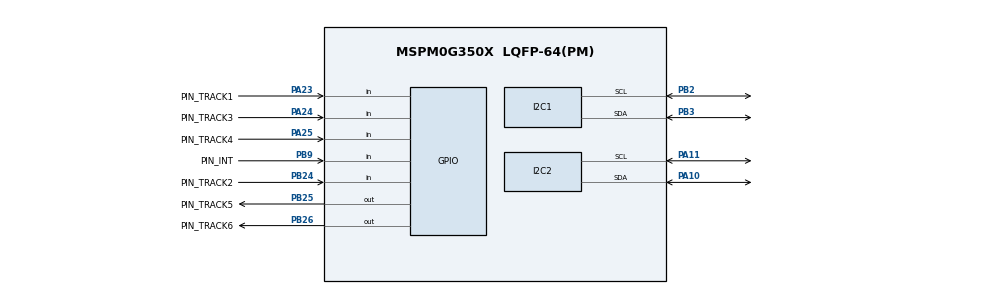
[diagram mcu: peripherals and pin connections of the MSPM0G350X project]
/**
 * @cliArgs --device "MSPM0G350X" --part "Default" --package "LQFP-64(PM)" --product "mspm0_sdk@2.05.01.00"
 * @versions {"tool":"1.24.0+4110"}
 */

/**
 * Import the modules used in this configuration.
 */
const GPIO   = scripting.addModule("/ti/driverlib/GPIO", {}, false);
const GPIO1  = GPIO.addInstance();
const GPIO2  = GPIO.addInstance();
const GPIO3  = GPIO.addInstance();
const GPIO4  = GPIO.addInstance();
const GPIO5  = GPIO.addInstance();
const GPIO6  = GPIO.addInstance();
const I2C    = scripting.addModule("/ti/driverlib/I2C", {}, false);
const I2C1   = I2C.addInstance();
const I2C2   = I2C.addInstance();
const PWM    = scripting.addModule("/ti/driverlib/PWM", {}, false);
const PWM1   = PWM.addInstance();
const PWM2   = PWM.addInstance();
const SYSCTL = scripting.addModule("/ti/driverlib/SYSCTL");
const UART   = scripting.addModule("/ti/driverlib/UART", {}, false);
const UART1  = UART.addInstance();

/**
 * Write custom configuration values to the imported modules.
 */
const divider7       = system.clockTree["PLL_PDIV"];
divider7.divideValue = 2;

const divider9       = system.clockTree["UDIV"];
divider9.divideValue = 2;

const multiplier2         = system.clockTree["PLL_QDIV"];
multiplier2.multiplyValue = 5;

const mux8       = system.clockTree["HSCLKMUX"];
mux8.inputSelect = "HSCLKMUX_SYSPLL2X";

GPIO1.$name                   = "GPIO_MOTOR";
GPIO1.associatedPins.create(5);
GPIO1.associatedPins[0].$name = "PIN_FL1";
GPIO1.associatedPins[1].$name = "PIN_FL2";
GPIO1.associatedPins[2].$name = "PIN_FR1";
GPIO1.associatedPins[3].$name = "PIN_FR2";
GPIO1.associatedPins[4].$name = "PIN_FSTBY";

const Board = scripting.addModule("/ti/driverlib/Board", {}, false);

GPIO2.$name                          = "GPIO_LED";
GPIO2.associatedPins[0].$name        = "PIN_LED1";
GPIO2.associatedPins[0].assignedPort = "PORTB";
GPIO2.associatedPins[0].assignedPin  = "22";

GPIO3.$name                          = "GPIO_BUTTON";
GPIO3.associatedPins[0].$name        = "PIN_S2";
GPIO3.associatedPins[0].direction    = "INPUT";
GPIO3.associatedPins[0].assignedPort = "PORTB";
GPIO3.associatedPins[0].assignedPin  = "21";

GPIO4.$name                               = "GPIO_LSM6DSV16X";
GPIO4.associatedPins[0].direction         = "INPUT";
GPIO4.associatedPins[0].$name             = "PIN_INT";
GPIO4.associatedPins[0].interruptEn       = true;
GPIO4.associatedPins[0].interruptPriority = "3";
GPIO4.associatedPins[0].polarity          = "RISE";
GPIO4.associatedPins[0].pin.$assign       = "PB9";

GPIO5.$name                   = "GPIO_BUZZER";
GPIO5.associatedPins[0].$name = "PIN_buzzer";

GPIO6.$name                         = "GPIO_TRACK";
GPIO6.associatedPins.create(6);
GPIO6.associatedPins[0].$name       = "PIN_TRACK1";
GPIO6.associatedPins[0].direction   = "INPUT";
GPIO6.associatedPins[0].pin.$assign = "PA23";
GPIO6.associatedPins[1].$name       = "PIN_TRACK2";
GPIO6.associatedPins[1].direction   = "INPUT";
GPIO6.associatedPins[1].pin.$assign = "PB24";
GPIO6.associatedPins[2].$name       = "PIN_TRACK3";
GPIO6.associatedPins[2].direction   = "INPUT";
GPIO6.associatedPins[2].pin.$assign = "PA24";
GPIO6.associatedPins[3].$name       = "PIN_TRACK4";
GPIO6.associatedPins[3].direction   = "INPUT";
GPIO6.associatedPins[3].pin.$assign = "PA25";
GPIO6.associatedPins[4].$name       = "PIN_TRACK5";
GPIO6.associatedPins[4].pin.$assign = "PB25";
GPIO6.associatedPins[5].$name       = "PIN_TRACK6";
GPIO6.associatedPins[5].pin.$assign = "PB26";

I2C1.$name                             = "I2C_OLED";
I2C1.basicEnableController             = true;
I2C1.basicControllerStandardBusSpeed   = "Fast";
I2C1.peripheral.$assign                = "I2C1";
I2C1.peripheral.sdaPin.$assign         = "PB3";
I2C1.peripheral.sclPin.$assign         = "PB2";
I2C1.sdaPinConfig.hideOutputInversion  = scripting.forceWrite(false);
I2C1.sdaPinConfig.onlyInternalResistor = scripting.forceWrite(false);
I2C1.sdaPinConfig.passedPeripheralType = scripting.forceWrite("Digital");
I2C1.sdaPinConfig.$name                = "ti_driverlib_gpio_GPIOPinGeneric6";
I2C1.sclPinConfig.hideOutputInversion  = scripting.forceWrite(false);
I2C1.sclPinConfig.onlyInternalResistor = scripting.forceWrite(false);
I2C1.sclPinConfig.passedPeripheralType = scripting.forceWrite("Digital");
I2C1.sclPinConfig.$name                = "ti_driverlib_gpio_GPIOPinGeneric7";

I2C2.$name                             = "I2C_LSM6DSV16X";
I2C2.basicEnableController             = true;
I2C2.basicControllerStandardBusSpeed   = "FastPlus";
I2C2.peripheral.sdaPin.$assign         = "PA10";
I2C2.peripheral.sclPin.$assign         = "PA11";
I2C2.sdaPinConfig.hideOutputInversion  = scripting.forceWrite(false);
I2C2.sdaPinConfig.onlyInternalResistor = scripting.forceWrite(false);
I2C2.sdaPinConfig.passedPeripheralType = scripting.forceWrite("Digital");
I2C2.sdaPinConfig.$name                = "ti_driverlib_gpio_GPIOPinGeneric8";
I2C2.sclPinConfig.hideOutputInversion  = scripting.forceWrite(false);
I2C2.sclPinConfig.onlyInternalResistor = scripting.forceWrite(false);
I2C2.sclPinConfig.passedPeripheralType = scripting.forceWrite("Digital");
I2C2.sclPinConfig.$name                = "ti_driverlib_gpio_GPIOPinGeneric9";

PWM1.$name                              = "PWM_MOTOR";
PWM1.timerCount                         = 8000;
PWM1.clockPrescale                      = 10;
PWM1.peripheral.$assign                 = "TIMA0";
PWM1.PWM_CHANNEL_0.$name                = "ti_driverlib_pwm_PWMTimerCC0";
PWM1.PWM_CHANNEL_0.dutyCycle            = 50;
PWM1.PWM_CHANNEL_1.$name                = "ti_driverlib_pwm_PWMTimerCC1";
PWM1.PWM_CHANNEL_1.dutyCycle            = 50;
PWM1.ccp0PinConfig.direction            = scripting.forceWrite("OUTPUT");
PWM1.ccp0PinConfig.hideOutputInversion  = scripting.forceWrite(false);
PWM1.ccp0PinConfig.onlyInternalResistor = scripting.forceWrite(false);
PWM1.ccp0PinConfig.passedPeripheralType = scripting.forceWrite("Digital");
PWM1.ccp0PinConfig.$name                = "ti_driverlib_gpio_GPIOPinGeneric0";
PWM1.ccp1PinConfig.direction            = scripting.forceWrite("OUTPUT");
PWM1.ccp1PinConfig.hideOutputInversion  = scripting.forceWrite(false);
PWM1.ccp1PinConfig.onlyInternalResistor = scripting.forceWrite(false);
PWM1.ccp1PinConfig.passedPeripheralType = scripting.forceWrite("Digital");
PWM1.ccp1PinConfig.$name                = "ti_driverlib_gpio_GPIOPinGeneric1";

PWM2.$name                              = "PWM_SERVO";
PWM2.timerCount                         = 8000;
PWM2.clockPrescale                      = 200;
PWM2.timerStartTimer                    = true;
PWM2.PWM_CHANNEL_0.$name                = "ti_driverlib_pwm_PWMTimerCC2";
PWM2.PWM_CHANNEL_1.$name                = "ti_driverlib_pwm_PWMTimerCC3";
PWM2.ccp0PinConfig.direction            = scripting.forceWrite("OUTPUT");
PWM2.ccp0PinConfig.hideOutputInversion  = scripting.forceWrite(false);
PWM2.ccp0PinConfig.onlyInternalResistor = scripting.forceWrite(false);
PWM2.ccp0PinConfig.passedPeripheralType = scripting.forceWrite("Digital");
PWM2.ccp0PinConfig.$name                = "ti_driverlib_gpio_GPIOPinGeneric4";
PWM2.ccp1PinConfig.direction            = scripting.forceWrite("OUTPUT");
PWM2.ccp1PinConfig.hideOutputInversion  = scripting.forceWrite(false);
PWM2.ccp1PinConfig.onlyInternalResistor = scripting.forceWrite(false);
PWM2.ccp1PinConfig.passedPeripheralType = scripting.forceWrite("Digital");
PWM2.ccp1PinConfig.$name                = "ti_driverlib_gpio_GPIOPinGeneric5";

SYSCTL.forceDefaultClkConfig = true;
SYSCTL.clockTreeEn           = true;
scripting.suppress("For best practices when the CPUCLK is running at 32MHz and above, clear the flash status bit using DL_FlashCTL_executeClearStatus\\(\\) before executing any flash operation\\. Otherwise there may be false positives\\.", SYSCTL);

UART1.$name                            = "UART_OPENMV";
UART1.enabledInterrupts                = ["RX"];
UART1.peripheral.$assign               = "UART0";
UART1.txPinConfig.direction            = scripting.forceWrite("OUTPUT");
UART1.txPinConfig.hideOutputInversion  = scripting.forceWrite(false);
UART1.txPinConfig.onlyInternalResistor = scripting.forceWrite(false);
UART1.txPinConfig.passedPeripheralType = scripting.forceWrite("Digital");
UART1.txPinConfig.$name                = "ti_driverlib_gpio_GPIOPinGeneric2";
UART1.rxPinConfig.hideOutputInversion  = scripting.forceWrite(false);
UART1.rxPinConfig.onlyInternalResistor = scripting.forceWrite(false);
UART1.rxPinConfig.passedPeripheralType = scripting.forceWrite("Digital");
UART1.rxPinConfig.$name                = "ti_driverlib_gpio_GPIOPinGeneric3";

/**
 * Pinmux solution for unlocked pins/peripherals. This ensures that minor changes to the automatic solver in a future
 * version of the tool will not impact the pinmux you originally saw.  These lines can be completely deleted in order to
 * re-solve from scratch.
 */
GPIO1.associatedPins[0].pin.$suggestSolution = "PB14";
GPIO1.associatedPins[1].pin.$suggestSolution = "PB15";
GPIO1.associatedPins[2].pin.$suggestSolution = "PB16";
GPIO1.associatedPins[3].pin.$suggestSolution = "PA12";
GPIO1.associatedPins[4].pin.$suggestSolution = "PA13";
Board.peripheral.$suggestSolution            = "DEBUGSS";
Board.peripheral.swclkPin.$suggestSolution   = "PA20";
Board.peripheral.swdioPin.$suggestSolution   = "PA19";
GPIO2.associatedPins[0].pin.$suggestSolution = "PB22";
GPIO3.associatedPins[0].pin.$suggestSolution = "PB21";
GPIO5.associatedPins[0].pin.$suggestSolution = "PB13";
I2C2.peripheral.$suggestSolution             = "I2C0";
PWM1.peripheral.ccp0Pin.$suggestSolution     = "PA21";
PWM1.peripheral.ccp1Pin.$suggestSolution     = "PA22";
PWM2.peripheral.$suggestSolution             = "TIMA1";
PWM2.peripheral.ccp0Pin.$suggestSolution     = "PA15";
PWM2.peripheral.ccp1Pin.$suggestSolution     = "PA16";
UART1.peripheral.rxPin.$suggestSolution      = "PA1";
UART1.peripheral.txPin.$suggestSolution      = "PA0";
